# DMASS0_CBASS_0_CBASS_DMSC_QOS register map
Vendor: Texas Instruments
Peripheral module from a debugger description file (folder am243x).
Registers are 32-bit, read-write, reset 0x7000 unless marked. A register's access mark holds for its fields unless they carry their own. Offsets are as the file gives them; lines under a group give offsets from that group; [hi:lo] are bit positions; {n}, {i} and the like mark numbered series; 'fields as' and 'values as' point back to an identical list; <NAME> marks a mode.

## DMASS0_CBASS_0_CBASS_DMSC_QOS
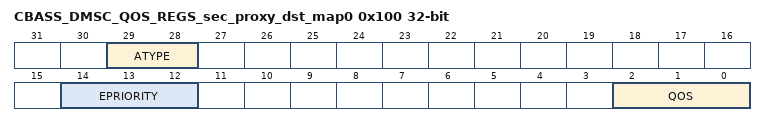
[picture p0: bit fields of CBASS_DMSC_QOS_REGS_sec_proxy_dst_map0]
0x100 CBASS_DMSC_QOS_REGS_sec_proxy_dst_map0 — The Map Register defines the fields for the master sec_proxy.dst per channel.
  [29:28] ATYPE — epriority signal for channel N. 0 = physical. 1 = intermediate. 2 = virtual. 3 = physical with coherence.
  [14:12] EPRIORITY — epriority signal for channel N.
  [2:0] QOS — qos signal for channel N.
